# FSS_HYPERBUS1P0_0_HYPERBUS_SYSCFG_0FC30000h register map
Vendor: Texas Instruments
Peripheral module from a debugger description file (folder AM275x).
Registers are 32-bit, read-only, reset 0x0 unless marked. A register's access mark holds for its fields unless they carry their own. Offsets are as the file gives them; lines under a group give offsets from that group; [hi:lo] are bit positions; {n}, {i} and the like mark numbered series; 'fields as' and 'values as' point back to an identical list; <NAME> marks a mode.

## hyperbus_syscfg
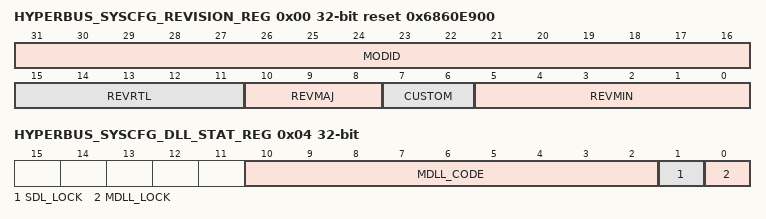
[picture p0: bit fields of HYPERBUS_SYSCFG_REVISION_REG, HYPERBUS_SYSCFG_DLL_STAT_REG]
0x00 HYPERBUS_SYSCFG_REVISION_REG reset 0x6860E900 — The Revision Register contains the major and minor revisions for the module
  [31:16] MODID — Module ID field Reset Source: rst_n
  [15:11] REVRTL — RTL revision. Will vary depending on release Reset Source: rst_n
  [10:8] REVMAJ — Major revision Reset Source: rst_n
  [7:6] CUSTOM — Custom Reset Source: rst_n
  [5:0] REVMIN — Minor revision Reset Source: rst_n
0x04 HYPERBUS_SYSCFG_DLL_STAT_REG — DLL status register
  [10:2] MDLL_CODE — MDLL code. The target delay line length that is currently enabled is determined by the MDLL code value Reset Source: rst_n
  [1] SDL_LOCK — SDL lock. When this bit is set, it indicates that the target delay line in the MDLL is locked. Reset Source: rst_n
  [0] MDLL_LOCK — MDLL lock. When this bit is set, it indicates that the initiator delay line in the MDLL is locked. Reset Source: rst_n
0x08 HYPERBUS_SYSCFG_RAM_STAT_REG — RAM status register
  [0] INIT_DONE — FIFO RAM initialization done. When this bit is set, t indicates that all the FIFO RAM auto initialization is complete. Software should check that this bit is set before initiating transactions to the external memory Reset Source: rst_n
